# STM32WL3R register map
File version: 1.0
CPU: CM0+ r0p0, little endian, MPU, no FPU, 4 interrupt priority bits
Registers are 32-bit, read-write, reset 0x0 unless marked. A register's access mark holds for its fields unless they carry their own. Offsets are from the block's base; [hi:lo] are bit positions.

## TIMER16 — TIMER16 address block description
Base 0x40005000
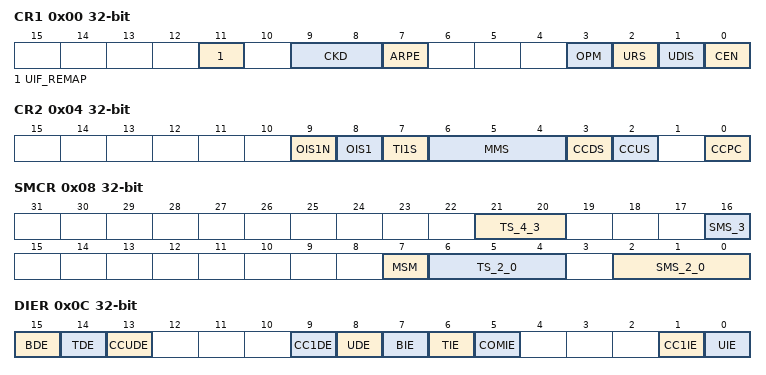
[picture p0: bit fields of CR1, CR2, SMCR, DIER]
0x00 CR1 (reset mask 0xF)
  [11] UIF_REMAP — UIFREMAP: UIF status bit remapping
  [9:8] CKD — CKD[1:0]: Clock division
  [7] ARPE — ARPE: Auto-reload preload enable
  [3] OPM — OPM: One pulse mode
  [2] URS — URS: Update request source
  [1] UDIS — UDIS: Update disable
  [0] CEN — CEN: Counter enable
0x04 CR2 (reset mask 0xF)
  [9] OIS1N — OIS1N: Output Idle state 1 (OC1N output)
  [8] OIS1 — OIS1: Output Idle state 1 (OC1 output)
  [7] TI1S — TI1S: TI1 selection
  [6:4] MMS — MMS[2:0]: Master mode selection
  [3] CCDS — CCDS: Capture/compare DMA selection
  [2] CCUS — CCUS: Capture/compare control update selection
  [0] CCPC — CCPC: Capture/compare preloaded control
0x08 SMCR (reset mask 0xF)
  [21:20] TS_4_3 — TS[4:0]: Trigger selection.
  [16] SMS_3 — SMS[3:0]: Slave mode selection.
  [7] MSM — MSM: Master/slave mode
  [6:4] TS_2_0 — TS[4:0]: Trigger selection
  [2:0] SMS_2_0 — SMS[3:0]: Slave mode selection
0x0C DIER (reset mask 0xF)
  [15] BDE — BDE: Break DMA request Enable.
  [14] TDE — TDE: Trigger DMA request enable
  [13] CCUDE — CCUDE: CC-Update DMA request Enable.
  [9] CC1DE — CC1DE: Capture/Compare 1 DMA request enable
  [8] UDE — UDE: Update DMA request enable
  [7] BIE — BIE: Break interrupt enable
  [6] TIE — TIE: Trigger interrupt enable
  [5] COMIE — COMIE: COM interrupt enable
  [1] CC1IE — CC1IE: Capture/Compare 1 interrupt enable
  [0] UIE — UIE: Update interrupt enable
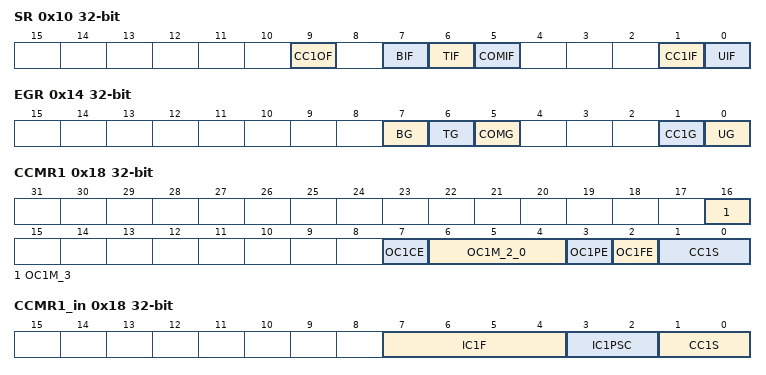
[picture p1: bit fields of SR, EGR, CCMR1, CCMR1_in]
0x10 SR (reset mask 0xF)
  [9] CC1OF — CC1OF: Capture/Compare 1 overcapture flag
  [7] BIF — BIF: Break interrupt flag
  [6] TIF — TIF: Trigger interrupt flag
  [5] COMIF — COMIF: COM interrupt flag
  [1] CC1IF — CC1IF: Capture/Compare 1 interrupt flag
  [0] UIF — UIF: Update interrupt flag
0x14 EGR (reset mask 0xF)
  [7] BG wo — BG: Break generation
  [6] TG wo — TG: Trigger generation
  [5] COMG wo — COMG: Capture/Compare control update generation
  [1] CC1G wo — CC1G: Capture/Compare 1 generation
  [0] UG wo — UG: Update generation
0x18 CCMR1 (reset mask 0xF)
  [16] OC1M_3 — OC1M[3]: Output Compare 1 mode (bit 3)
  [7] OC1CE — OC1CE: Output Compare 1 Clear Enable.
  [6:4] OC1M_2_0 — OC1M[2:0]: Output Compare 1 mode (bits 2 to 0)
  [3] OC1PE — OC1PE: Output Compare 1 preload enable
  [2] OC1FE — OC1FE: Output Compare 1 fast enable
  [1:0] CC1S — CC1S: Capture/Compare 1 Selection
0x18 CCMR1_in (reset mask 0xF) (alternate view of CCMR1)
  [7:4] IC1F — Bits 7:4 IC1F[3:0]: Input capture 1 filter
  [3:2] IC1PSC — IC1PSC: Input capture 1 prescaler
  [1:0] CC1S — CC1S: Capture/Compare 1 Selection
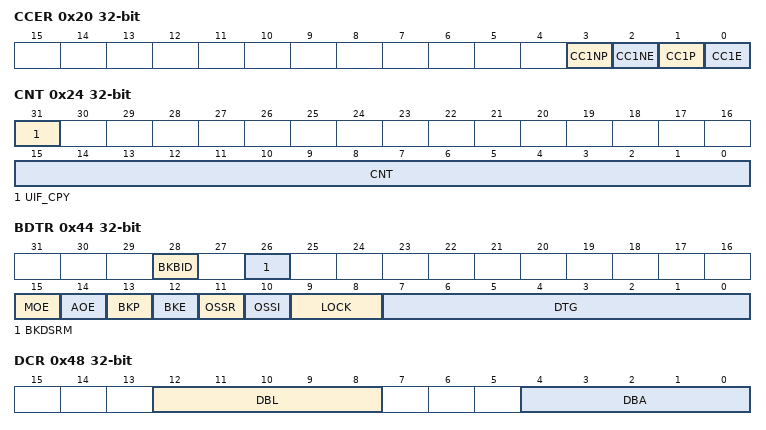
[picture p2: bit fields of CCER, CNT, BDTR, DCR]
0x20 CCER
  [3] CC1NP — CC1NP: Capture/Compare 1 complementary output polarity
  [2] CC1NE — CC1NE: Capture/Compare 1 complementary output enable
  [1] CC1P — CC1P: Capture/Compare 1 output polarity
    1=Non-inverted/both edges
  [0] CC1E — CC1E: Capture/Compare 1 output enable
0x24 CNT (reset mask 0xF)
  [31] UIF_CPY ro — UIFCPY: UIF Copy
  [15:0] CNT — CNT[15:0]: Counter value
0x28 PSC (reset mask 0xF)
  [15:0] PSC — PSC[15:0]: Prescaler value
0x2C ARR reset 0xFFFF
  [15:0] ARR — ARR[15:0]: Prescaler value
0x30 RCR (reset mask 0xF)
  [7:0] REP — REP[7:0]: Repetition counter value
0x34 CCR1 (reset mask 0xF)
  [15:0] CCR — CCR1[15:0]: Capture/Compare 1 value
0x44 BDTR (reset mask 0xF)
  [28] BKBID — BKBID: Break Bidirectional
  [26] BKDSRM — BKDSRM: Break Disarm
  [15] MOE — MOE: Main output enable
  [14] AOE — AOE: Automatic output enable
    0=MOE can be set only by software; 1=MOE can be set by software or automatically at the next update event (if the break input is
  [13] BKP — BKP: Break polarity
  [12] BKE — BKE: Break enable
    0=Break inputs (BRK) disabled
  [11] OSSR — OSSR: Off-state selection for Run mode
  [10] OSSI — OSSI: Off-state selection for Idle mode
  [9:8] LOCK — LOCK[1:0]: Lock configuration
  [7:0] DTG — DTG[7:0]: Dead-time generator setup
0x48 DCR (reset mask 0xF)
  [12:8] DBL — DBL[4:0]: DMA burst length
  [4:0] DBA — DBA[4:0]: DMA base address
0x4C DMAR (reset mask 0xF)
  [15:0] DMAB — DMAB[15:0]: DMA register for burst accesses
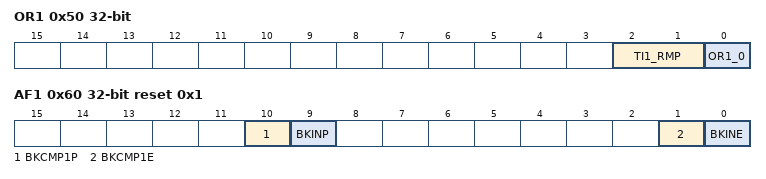
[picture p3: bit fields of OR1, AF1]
0x50 OR1
  [2:1] TI1_RMP — TI1_RMP[1:0]: Timer 16 input 1 connection
  [0] OR1_0 — Not used in Blue51.
0x60 AF1 reset 0x1 (reset mask 0xF)
  [10] BKCMP1P — BKCMP1P: BRK COMP1 input polarity.
  [9] BKINP — BKINP: BRK BKIN input polarity.
  [1] BKCMP1E — BKCMP1E: BRK COMP1 enable.
  [0] BKINE — BKINE: BRK BKIN enable.
0x68 TISEL
  [3:0] TI1SEL — TI1SEL[3:0]: selects TI1[0] to TI1[15] input
